# STM32G431VBT7 register map
File version: 1.0
Registers are 32-bit, access not given, reset 0x0 unless marked. A register's access mark holds for its fields unless they carry their own. Offsets are from the block's base; [hi:lo] are bit positions; {n}, {i} and the like mark numbered series.

## I2C1
Base 0x40005400
Same registers: I2C2 0x40005800, I2C3 0x40007800
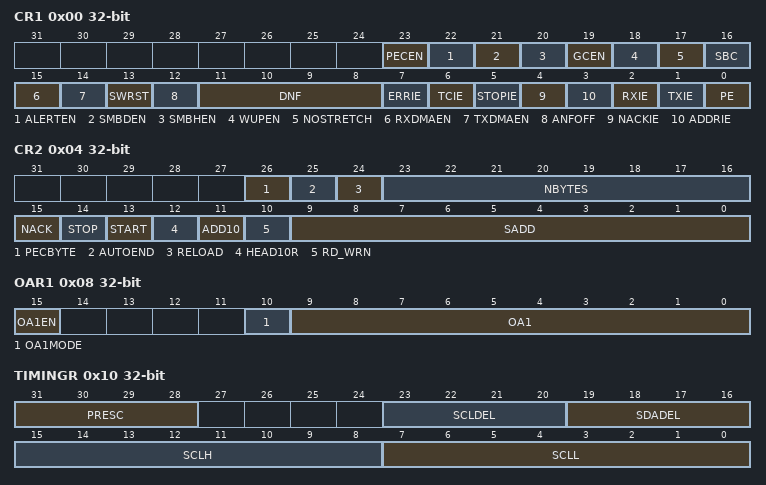
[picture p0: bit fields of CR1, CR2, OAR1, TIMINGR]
0x00 CR1
  [23] PECEN, [22] ALERTEN, [21] SMBDEN, [20] SMBHEN, [19] GCEN, [18] WUPEN, [17] NOSTRETCH, [16] SBC, [15] RXDMAEN, [14] TXDMAEN, [13] SWRST, [12] ANFOFF, [11:8] DNF, [7] ERRIE, [6] TCIE, [5] STOPIE, [4] NACKIE, [3] ADDRIE, [2] RXIE, [1] TXIE, [0] PE
0x04 CR2
  [26] PECBYTE, [25] AUTOEND, [24] RELOAD, [23:16] NBYTES, [15] NACK, [14] STOP, [13] START, [12] HEAD10R, [11] ADD10, [10] RD_WRN, [9:0] SADD
0x08 OAR1
  [15] OA1EN, [10] OA1MODE, [9:0] OA1
0x0C OAR2
  [15] OA2EN, [10] OA2MASK04, [10:9] OA2MASK06, [10:8] OA2MSK, [7:1] OA2
0x10 TIMINGR
  [31:28] PRESC, [23:20] SCLDEL, [19:16] SDADEL, [15:8] SCLH, [7:0] SCLL
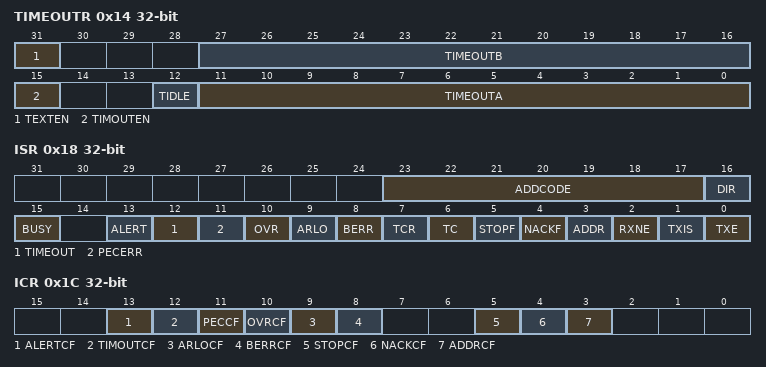
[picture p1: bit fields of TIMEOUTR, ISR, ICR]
0x14 TIMEOUTR
  [31] TEXTEN, [27:16] TIMEOUTB, [15] TIMOUTEN, [12] TIDLE, [11:0] TIMEOUTA
0x18 ISR
  [23:17] ADDCODE, [16] DIR, [15] BUSY, [13] ALERT, [12] TIMEOUT, [11] PECERR, [10] OVR, [9] ARLO, [8] BERR, [7] TCR, [6] TC, [5] STOPF, [4] NACKF, [3] ADDR, [2] RXNE, [1] TXIS, [0] TXE
0x1C ICR
  [13] ALERTCF, [12] TIMOUTCF, [11] PECCF, [10] OVRCF, [9] ARLOCF, [8] BERRCF, [5] STOPCF, [4] NACKCF, [3] ADDRCF
0x20 PECR
  [7:0] PEC
0x24 RXDR
  [7:0] RXDATA
0x28 TXDR
  [7:0] TXDATA

## USB
Base 0x40005C00
{0x0+4i} EP{i}R 16-bit (i=0..7)
0x40 CNTR 16-bit
0x44 ISTR 16-bit
0x48 FNR 16-bit
0x4C DADDR 16-bit
0x50 BTABLE 16-bit
0x54 LPMCSR 16-bit
0x58 BCDR 16-bit

## FDCAN1
Base 0x40006400
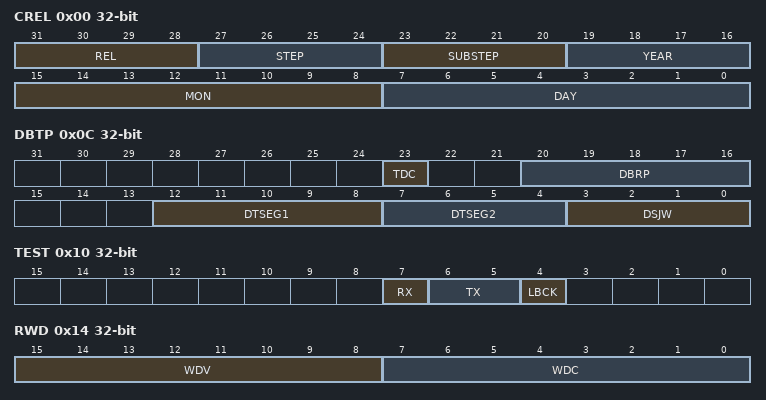
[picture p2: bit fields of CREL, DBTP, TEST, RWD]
0x00 CREL
  [31:28] REL, [27:24] STEP, [23:20] SUBSTEP, [19:16] YEAR, [15:8] MON, [7:0] DAY
0x04 ENDN
  [31:0] ETV
0x0C DBTP
  [23] TDC, [20:16] DBRP, [12:8] DTSEG1, [7:4] DTSEG2, [3:0] DSJW
0x10 TEST
  [7] RX, [6:5] TX, [4] LBCK
0x14 RWD
  [15:8] WDV, [7:0] WDC
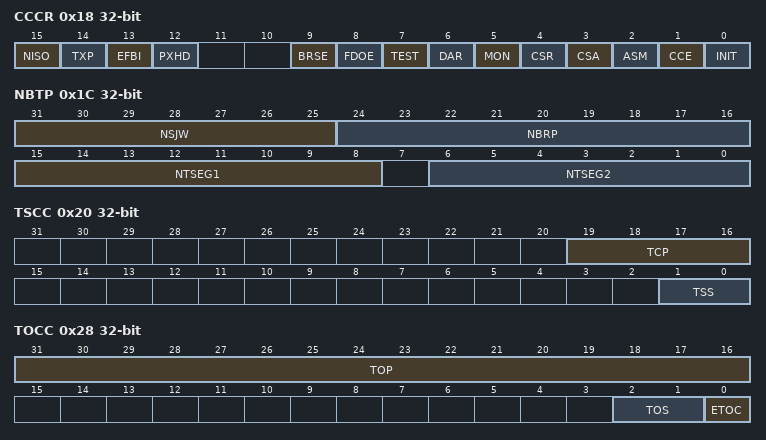
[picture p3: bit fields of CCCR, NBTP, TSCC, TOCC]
0x18 CCCR
  [15] NISO, [14] TXP, [13] EFBI, [12] PXHD, [9] BRSE, [8] FDOE, [7] TEST, [6] DAR, [5] MON, [4] CSR, [3] CSA, [2] ASM, [1] CCE, [0] INIT
0x1C NBTP
  [31:25] NSJW, [24:16] NBRP, [15:8] NTSEG1, [6:0] NTSEG2
0x20 TSCC
  [19:16] TCP, [1:0] TSS
0x24 TSCV
  [15:0] TSC
0x28 TOCC
  [31:16] TOP, [2:1] TOS, [0] ETOC
0x2C TOCV
  [15:0] TOC
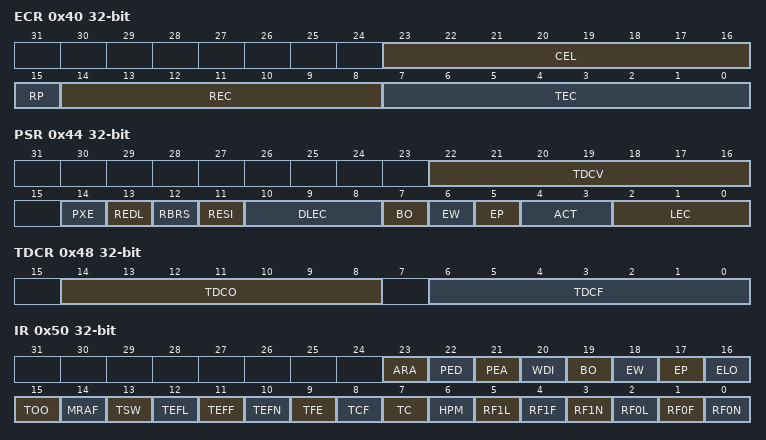
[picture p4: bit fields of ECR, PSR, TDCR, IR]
0x40 ECR
  [23:16] CEL, [15] RP, [14:8] REC, [7:0] TEC
0x44 PSR
  [22:16] TDCV, [14] PXE, [13] REDL, [12] RBRS, [11] RESI, [10:8] DLEC, [7] BO, [6] EW, [5] EP, [4:3] ACT, [2:0] LEC
0x48 TDCR
  [14:8] TDCO, [6:0] TDCF
0x50 IR
  [23] ARA, [22] PED, [21] PEA, [20] WDI, [19] BO, [18] EW, [17] EP, [16] ELO, [15] TOO, [14] MRAF, [13] TSW, [12] TEFL, [11] TEFF, [10] TEFN, [9] TFE, [8] TCF, [7] TC, [6] HPM, [5] RF1L, [4] RF1F, [3] RF1N, [2] RF0L, [1] RF0F, [0] RF0N
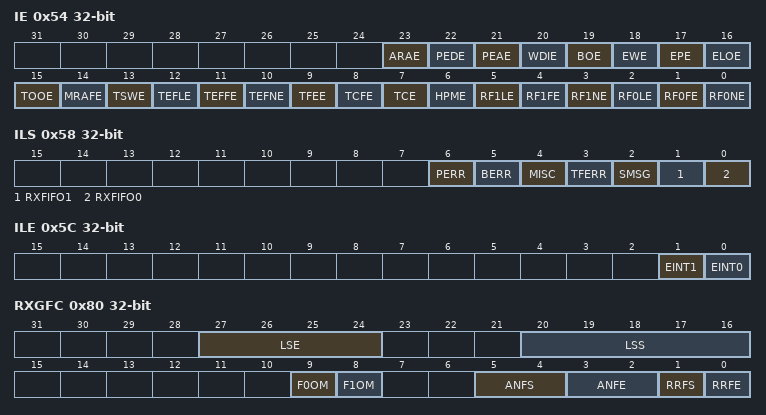
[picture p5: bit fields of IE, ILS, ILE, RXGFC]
0x54 IE
  [23] ARAE, [22] PEDE, [21] PEAE, [20] WDIE, [19] BOE, [18] EWE, [17] EPE, [16] ELOE, [15] TOOE, [14] MRAFE, [13] TSWE, [12] TEFLE, [11] TEFFE, [10] TEFNE, [9] TFEE, [8] TCFE, [7] TCE, [6] HPME, [5] RF1LE, [4] RF1FE, [3] RF1NE, [2] RF0LE, [1] RF0FE, [0] RF0NE
0x58 ILS
  [6] PERR, [5] BERR, [4] MISC, [3] TFERR, [2] SMSG, [1] RXFIFO1, [0] RXFIFO0
0x5C ILE
  [1] EINT1, [0] EINT0
0x80 RXGFC
  [27:24] LSE, [20:16] LSS, [9] F0OM, [8] F1OM, [5:4] ANFS, [3:2] ANFE, [1] RRFS, [0] RRFE
0x84 XIDAM
  [28:0] EIDM
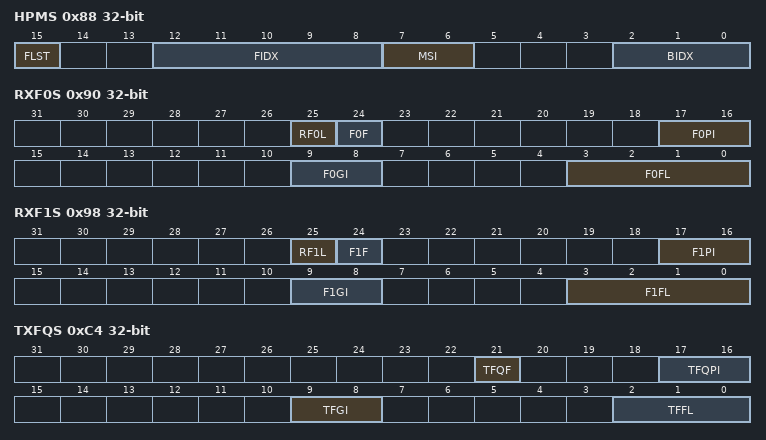
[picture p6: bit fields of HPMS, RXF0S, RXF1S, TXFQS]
0x88 HPMS
  [15] FLST, [12:8] FIDX, [7:6] MSI, [2:0] BIDX
0x90 RXF0S
  [25] RF0L, [24] F0F, [17:16] F0PI, [9:8] F0GI, [3:0] F0FL
0x94 RXF0A
  [2:0] F0AI
0x98 RXF1S
  [25] RF1L, [24] F1F, [17:16] F1PI, [9:8] F1GI, [3:0] F1FL
0x9C RXF1A
  [2:0] F1AI
0xC0 TXBC
  [24] TFQM
0xC4 TXFQS
  [21] TFQF, [17:16] TFQPI, [9:8] TFGI, [2:0] TFFL
0xC8 TXBRP
  [2:0] TRP
0xCC TXBAR
  [2:0] AR
0xD0 TXBCR
  [2:0] CR
0xD4 TXBTO
  [2:0] TO
0xD8 TXBCF
  [2:0] CF
0xDC TXBTIE
  [2:0] TIE
0xE0 TXBCIE
  [2:0] CFIE
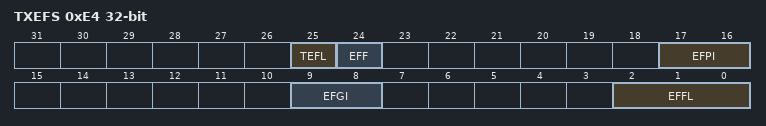
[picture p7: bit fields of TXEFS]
0xE4 TXEFS
  [25] TEFL, [24] EFF, [17:16] EFPI, [9:8] EFGI, [2:0] EFFL
0xE8 TXEFA
  [1:0] EFAI

## FDCAN_CONFIG
Base 0x40006500
0x00 CKDIV
  [3:0] PDIV

## PWR
Base 0x40007000
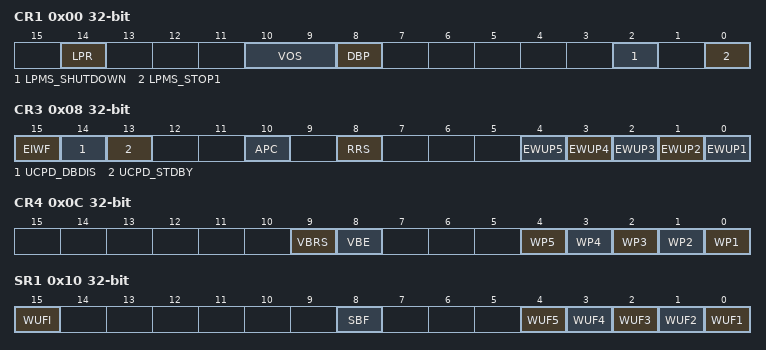
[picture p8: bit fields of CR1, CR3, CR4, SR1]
0x00 CR1
  [14] LPR, [10:9] VOS, [8] DBP, [2] LPMS_SHUTDOWN, [0] LPMS_STOP1
0x04 CR2
  [n+3] PVME{n} (n=1..4), [3] PLS_LEV4, [3:2] PLS_LEV6, [3:1] PLS_LEV7, [0] PVDE
0x08 CR3
  [15] EIWF, [14] UCPD_DBDIS, [13] UCPD_STDBY, [10] APC, [8] RRS, [n-1] EWUP{n} (n=1..5)
0x0C CR4
  [9] VBRS, [8] VBE, [n-1] WP{n} (n=1..5)
0x10 SR1
  [15] WUFI, [8] SBF, [n-1] WUF{n} (n=1..5)
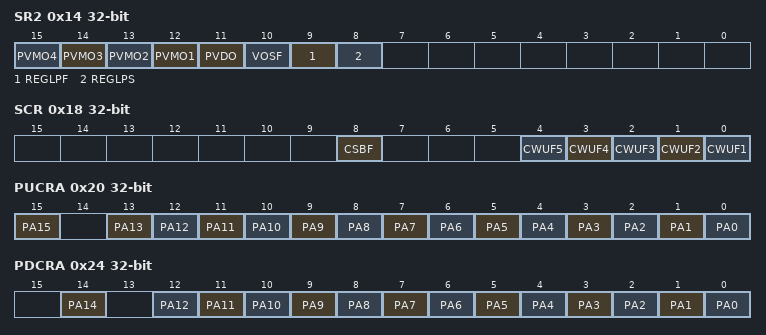
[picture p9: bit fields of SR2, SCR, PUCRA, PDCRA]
0x14 SR2
  [n+11] PVMO{n} (n=1..4), [11] PVDO, [10] VOSF, [9] REGLPF, [8] REGLPS
0x18 SCR
  [8] CSBF, [n-1] CWUF{n} (n=1..5)
0x20 PUCRA
  [15] PA15, [n] PA{n} (n=0..13)
0x24 PDCRA
  [14] PA14, [n] PA{n} (n=0..12)
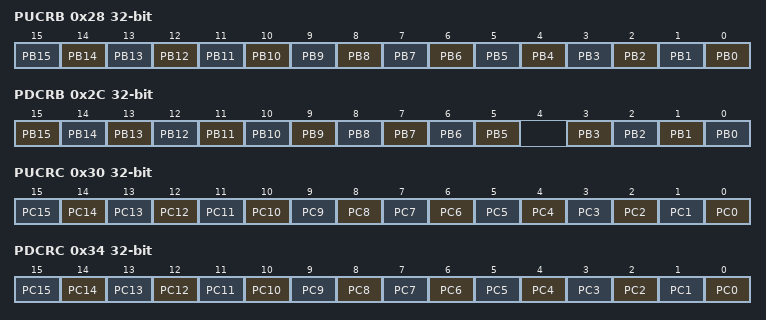
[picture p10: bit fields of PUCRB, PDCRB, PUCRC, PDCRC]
0x28 PUCRB
  [n] PB{n} (n=0..15)
0x2C PDCRB
  [n] PB{n} (n=5..15), [n] PB{n} (n=0..3)
0x30 PUCRC
  [n] PC{n} (n=0..15)
0x34 PDCRC
  [n] PC{n} (n=0..15)
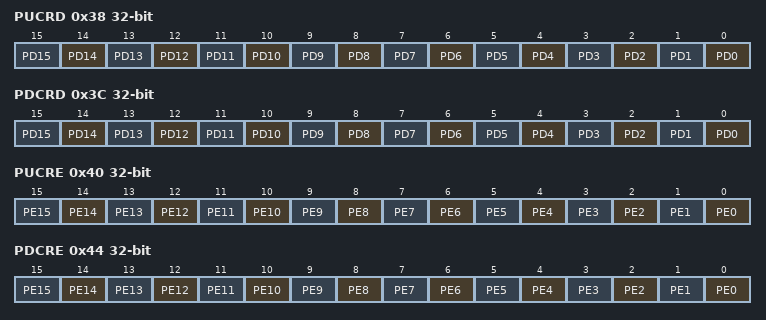
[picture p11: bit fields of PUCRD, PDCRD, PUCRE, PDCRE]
0x38 PUCRD
  [n] PD{n} (n=0..15)
0x3C PDCRD
  [n] PD{n} (n=0..15)
0x40 PUCRE
  [n] PE{n} (n=0..15)
0x44 PDCRE
  [n] PE{n} (n=0..15)
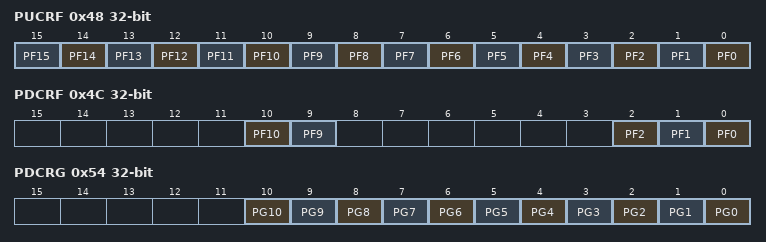
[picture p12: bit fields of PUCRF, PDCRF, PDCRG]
0x48 PUCRF
  [n] PF{n} (n=0..15)
0x4C PDCRF
  [10] PF10, [9] PF9, [2] PF2, [1] PF1, [0] PF0
0x50 PUCRG
  [10] PG10
0x54 PDCRG
  [n] PG{n} (n=0..10)
0x80 CR5
  [8] R1MODE
